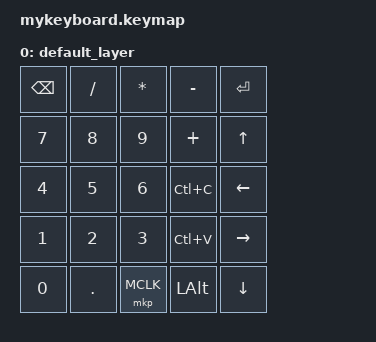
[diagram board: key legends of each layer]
#include <behaviors.dtsi>
#include <dt-bindings/zmk/keys.h>
#include <dt-bindings/zmk/bt.h>
#include <dt-bindings/zmk/mouse.h>

/ {
    keymap {
        compatible = "zmk,keymap";

        default_layer {
            bindings = 
                &kp BSPC     &kp SLASH    &kp STAR         &kp MINUS    &kp RET
                &kp N7       &kp N8       &kp N9           &kp PLUS     &kp UP
                &kp N4       &kp N5       &kp N6           &kp LC(C)    &kp LEFT
                &kp N1       &kp N2       &kp N3           &kp LC(V)    &kp RIGHT
                &kp N0       &kp DOT      &mkp MCLK        &kp LALT     &kp DOWN
            >;
        };
    };
};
